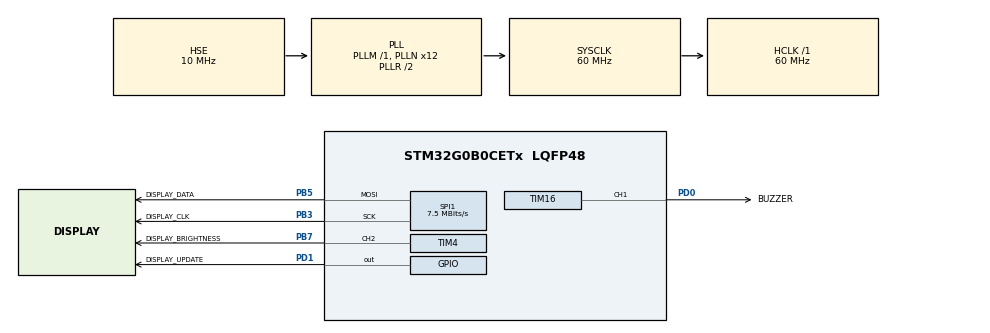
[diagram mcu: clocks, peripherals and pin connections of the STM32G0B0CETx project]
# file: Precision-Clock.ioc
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Dma.Request0=SPI1_TX
Dma.SPI1_TX.0.Direction=DMA_MEMORY_TO_PERIPH
Dma.SPI1_TX.0.EventEnable=DISABLE
Dma.SPI1_TX.0.Instance=DMA1_Channel1
Dma.SPI1_TX.0.MemDataAlignment=DMA_MDATAALIGN_BYTE
Dma.SPI1_TX.0.MemInc=DMA_MINC_ENABLE
Dma.SPI1_TX.0.Mode=DMA_NORMAL
Dma.SPI1_TX.0.PeriphDataAlignment=DMA_PDATAALIGN_BYTE
Dma.SPI1_TX.0.PeriphInc=DMA_PINC_DISABLE
Dma.SPI1_TX.0.Polarity=HAL_DMAMUX_REQ_GEN_RISING
Dma.SPI1_TX.0.Priority=DMA_PRIORITY_HIGH
Dma.SPI1_TX.0.RequestNumber=1
Dma.SPI1_TX.0.SignalID=NONE
Dma.SPI1_TX.0.SyncEnable=DISABLE
Dma.SPI1_TX.0.SyncPolarity=HAL_DMAMUX_SYNC_NO_EVENT
Dma.SPI1_TX.0.SyncRequestNumber=1
Dma.SPI1_TX.0.SyncSignalID=NONE
FREERTOS.Tasks01=defaultTask,24,512,StartDefaultTask,Default,NULL,Dynamic,NULL,NULL;brightnessTask,24,512,startBrightnessTask,As weak,NULL,Static,brightnessTaskBuffer,brightnessTaskControlBlock;displayRefreshTask,24,512,startDisplayRefreshTask,As weak,NULL,Static,displayRefreshTaskBuffer,displayRefreshTaskControlBlock
FREERTOS.configMAX_TASK_NAME_LEN=32
FREERTOS.configMINIMAL_STACK_SIZE=512
Mcu.Family=STM32G0
Mcu.Name=STM32G0B0CETx
Mcu.Package=LQFP48
NVIC.DMA1_Channel1_IRQn=true\:3\:0\:false\:false\:true\:true\:false\:true\:true
NVIC.TIM6_IRQn=true\:3\:0\:false\:false\:true\:false\:false\:true\:true
NVIC.TimeBase=TIM6_IRQn
NVIC.TimeBaseIP=TIM6
PA13.Mode=Serial_Wire
PA13.Signal=SYS_SWDIO
PA14-BOOT0.Mode=Serial_Wire
PA14-BOOT0.Signal=SYS_SWCLK
PB3.GPIO_Label=DISPLAY_CLK
PB3.GPIO_Speed=GPIO_SPEED_FREQ_VERY_HIGH
PB3.Mode=TX_Only_Simplex_Unidirect_Master
PB3.PinState=GPIO_PIN_RESET
PB3.Signal=SPI1_SCK
PB5.GPIO_Label=DISPLAY_DATA
PB5.GPIO_Speed=GPIO_SPEED_FREQ_VERY_HIGH
PB5.Mode=TX_Only_Simplex_Unidirect_Master
PB5.PinState=GPIO_PIN_RESET
PB5.Signal=SPI1_MOSI
PB7.GPIO_Label=DISPLAY_BRIGHTNESS
PB7.GPIO_Speed=GPIO_SPEED_FREQ_HIGH
PB7.Signal=S_TIM4_CH2
PC14-OSC32_IN\ (PC14).Mode=LSE-External-Oscillator
PC14-OSC32_IN\ (PC14).Signal=RCC_OSC32_IN
PC15-OSC32_OUT\ (PC15).Mode=LSE-External-Oscillator
PC15-OSC32_OUT\ (PC15).Signal=RCC_OSC32_OUT
PD0.GPIO_Label=BUZZER
PD0.Signal=S_TIM16_CH1
PD1.GPIO_Label=DISPLAY_UPDATE
PD1.GPIO_PuPd=GPIO_PULLDOWN
PD1.GPIO_Speed=GPIO_SPEED_FREQ_HIGH
PD1.Signal=GPIO_Output
PF0-OSC_IN\ (PF0).Mode=HSE-External-Clock-Source
PF0-OSC_IN\ (PF0).Signal=RCC_OSC_IN
ProjectManager.HeapSize=0x200
ProjectManager.StackSize=0x400
ProjectManager.TargetToolchain=CMake
RCC.ADCFreq_Value=60000000
RCC.AHBFreq_Value=60000000
RCC.CortexFreq_Value=60000000
RCC.EXTERNAL_CLOCK_VALUE=48000
RCC.HCLKFreq_Value=60000000
RCC.HSE_VALUE=10000000
RCC.HSI_VALUE=16000000
RCC.PLLN=12
RCC.PLLQ=RCC_PLLQ_DIV5
RCC.PLLSourceVirtual=RCC_PLLSOURCE_HSE
RCC.RTCClockSelection=RCC_RTCCLKSOURCE_LSE
RCC.SYSCLKFreq_VALUE=60000000
RCC.SYSCLKSource=RCC_SYSCLKSOURCE_PLLCLK
RCC.USBFreq_Value=24000000
RCC.VCOOutputFreq_Value=120000000
SH.S_TIM16_CH1.0=TIM16_CH1,PWM Generation1 CH1
SH.S_TIM4_CH2.0=TIM4_CH2,PWM Generation2 CH2
SPI1.BaudRatePrescaler=SPI_BAUDRATEPRESCALER_8
SPI1.CalculateBaudRate=7.5 MBits/s
SPI1.DataSize=SPI_DATASIZE_8BIT
SPI1.Direction=SPI_DIRECTION_2LINES
SPI1.Mode=SPI_MODE_MASTER
SPI1.NSSPMode=SPI_NSS_PULSE_DISABLE
SPI1.VirtualType=VM_MASTER
TIM16.AutoReloadPreload=TIM_AUTORELOAD_PRELOAD_ENABLE
TIM16.Channel=TIM_CHANNEL_1
TIM16.Period=999
TIM16.Prescaler=17143-1
TIM16.Pulse=999
TIM4.AutoReloadPreload=TIM_AUTORELOAD_PRELOAD_ENABLE
TIM4.Channel-PWM\ Generation2\ CH2=TIM_CHANNEL_2
TIM4.OCMode_PWM-PWM\ Generation2\ CH2=TIM_OCMODE_PWM1
TIM4.Period=999
TIM4.Prescaler=6-1
TIM4.Pulse-PWM\ Generation2\ CH2=999
VP_FREERTOS_VS_CMSIS_V2.Mode=CMSIS_V2
VP_RTC_VS_RTC_Activate.Mode=RTC_Enabled
VP_SYS_VS_DBSignals.Mode=DisableDeadBatterySignals
VP_SYS_VS_tim6.Mode=TIM6
VP_TIM16_VS_ClockSourceINT.Mode=Enable_Timer
VP_TIM4_VS_ClockSourceINT.Mode=Internal
board=custom

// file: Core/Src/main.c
/* USER CODE BEGIN Header */
/**
  ******************************************************************************
  * @file           : main.c
  * @brief          : Main program body
  ******************************************************************************
  * @attention
  *
  * Copyright (c) 2026 STMicroelectronics.
  * All rights reserved.
  *
  * This software is licensed under terms that can be found in the LICENSE file
  * in the root directory of this software component.
  * If no LICENSE file comes with this software, it is provided AS-IS.
  *
  ******************************************************************************
  */
/* USER CODE END Header */
#include "main.h"
#include "cmsis_os.h"

typedef StaticTask_t osStaticThreadDef_t;

RTC_HandleTypeDef hrtc;

SPI_HandleTypeDef hspi1;
DMA_HandleTypeDef hdma_spi1_tx;

TIM_HandleTypeDef htim4;
TIM_HandleTypeDef htim16;

/* Definitions for defaultTask */
osThreadId_t defaultTaskHandle;
const osThreadAttr_t defaultTask_attributes = {
  .name = "defaultTask",
  .priority = (osPriority_t) osPriorityNormal,
  .stack_size = 512 * 4
};
/* Definitions for brightnessTask */
osThreadId_t brightnessTaskHandle;
uint32_t brightnessTaskBuffer[ 512 ];
osStaticThreadDef_t brightnessTaskControlBlock;
const osThreadAttr_t brightnessTask_attributes = {
  .name = "brightnessTask",
  .stack_mem = &brightnessTaskBuffer[0],
  .stack_size = sizeof(brightnessTaskBuffer),
  .cb_mem = &brightnessTaskControlBlock,
  .cb_size = sizeof(brightnessTaskControlBlock),
  .priority = (osPriority_t) osPriorityNormal,
};
/* Definitions for displayRefreshTask */
osThreadId_t displayRefreshTaskHandle;
uint32_t displayRefreshTaskBuffer[ 512 ];
osStaticThreadDef_t displayRefreshTaskControlBlock;
const osThreadAttr_t displayRefreshTask_attributes = {
  .name = "displayRefreshTask",
  .stack_mem = &displayRefreshTaskBuffer[0],
  .stack_size = sizeof(displayRefreshTaskBuffer),
  .cb_mem = &displayRefreshTaskControlBlock,
  .cb_size = sizeof(displayRefreshTaskControlBlock),
  .priority = (osPriority_t) osPriorityNormal,
};

void SystemClock_Config(void);
static void MX_GPIO_Init(void);
static void MX_DMA_Init(void);
static void MX_SPI1_Init(void);
static void MX_TIM4_Init(void);
static void MX_RTC_Init(void);
static void MX_TIM16_Init(void);
void StartDefaultTask(void *argument);
void startBrightnessTask(void *argument);
void startDisplayRefreshTask(void *argument);

int main(void)
{

  /* MCU Configuration--------------------------------------------------------*/

  /* Reset of all peripherals, Initializes the Flash interface and the Systick. */
  HAL_Init();

  /* Configure the system clock */
  SystemClock_Config();

  /* Initialize all configured peripherals */
  MX_GPIO_Init();
  MX_DMA_Init();
  MX_SPI1_Init();
  MX_TIM4_Init();
  MX_RTC_Init();
  MX_TIM16_Init();

  /* Init scheduler */
  osKernelInitialize();

  /* Create the thread(s) */
  /* creation of defaultTask */
  defaultTaskHandle = osThreadNew(StartDefaultTask, NULL, &defaultTask_attributes);

  /* creation of brightnessTask */
  brightnessTaskHandle = osThreadNew(startBrightnessTask, NULL, &brightnessTask_attributes);

  /* creation of displayRefreshTask */
  displayRefreshTaskHandle = osThreadNew(startDisplayRefreshTask, NULL, &displayRefreshTask_attributes);

  /* Start scheduler */
  osKernelStart();

  /* We should never get here as control is now taken by the scheduler */

  /* Infinite loop */
  while (1)
  {

  }
}

void SystemClock_Config(void)
{
  RCC_OscInitTypeDef RCC_OscInitStruct = {0};
  RCC_ClkInitTypeDef RCC_ClkInitStruct = {0};

  /** Configure the main internal regulator output voltage
  */
  HAL_PWREx_ControlVoltageScaling(PWR_REGULATOR_VOLTAGE_SCALE1);

  /** Configure LSE Drive Capability
  */
  HAL_PWR_EnableBkUpAccess();
  __HAL_RCC_LSEDRIVE_CONFIG(RCC_LSEDRIVE_LOW);

  /** Initializes the RCC Oscillators according to the specified parameters
  * in the RCC_OscInitTypeDef structure.
  */
  RCC_OscInitStruct.OscillatorType = RCC_OSCILLATORTYPE_HSE|RCC_OSCILLATORTYPE_LSE;
  RCC_OscInitStruct.HSEState = RCC_HSE_BYPASS;
  RCC_OscInitStruct.LSEState = RCC_LSE_ON;
  RCC_OscInitStruct.PLL.PLLState = RCC_PLL_ON;
  RCC_OscInitStruct.PLL.PLLSource = RCC_PLLSOURCE_HSE;
  RCC_OscInitStruct.PLL.PLLM = RCC_PLLM_DIV1;
  RCC_OscInitStruct.PLL.PLLN = 12;
  RCC_OscInitStruct.PLL.PLLP = RCC_PLLP_DIV2;
  RCC_OscInitStruct.PLL.PLLQ = RCC_PLLQ_DIV5;
  RCC_OscInitStruct.PLL.PLLR = RCC_PLLR_DIV2;
  if (HAL_RCC_OscConfig(&RCC_OscInitStruct) != HAL_OK)
  {
    Error_Handler();
  }

  /** Initializes the CPU, AHB and APB buses clocks
  */
  RCC_ClkInitStruct.ClockType = RCC_CLOCKTYPE_HCLK|RCC_CLOCKTYPE_SYSCLK
                              |RCC_CLOCKTYPE_PCLK1;
  RCC_ClkInitStruct.SYSCLKSource = RCC_SYSCLKSOURCE_PLLCLK;
  RCC_ClkInitStruct.AHBCLKDivider = RCC_SYSCLK_DIV1;
  RCC_ClkInitStruct.APB1CLKDivider = RCC_HCLK_DIV1;

  if (HAL_RCC_ClockConfig(&RCC_ClkInitStruct, FLASH_LATENCY_2) != HAL_OK)
  {
    Error_Handler();
  }
}

static void MX_RTC_Init(void)
{

  /** Initialize RTC Only
  */
  hrtc.Instance = RTC;
  hrtc.Init.HourFormat = RTC_HOURFORMAT_24;
  hrtc.Init.AsynchPrediv = 127;
  hrtc.Init.SynchPrediv = 255;
  hrtc.Init.OutPut = RTC_OUTPUT_DISABLE;
  hrtc.Init.OutPutRemap = RTC_OUTPUT_REMAP_NONE;
  hrtc.Init.OutPutPolarity = RTC_OUTPUT_POLARITY_HIGH;
  hrtc.Init.OutPutType = RTC_OUTPUT_TYPE_OPENDRAIN;
  hrtc.Init.OutPutPullUp = RTC_OUTPUT_PULLUP_NONE;
  if (HAL_RTC_Init(&hrtc) != HAL_OK)
  {
    Error_Handler();
  }

}

static void MX_SPI1_Init(void)
{

  /* SPI1 parameter configuration*/
  hspi1.Instance = SPI1;
  hspi1.Init.Mode = SPI_MODE_MASTER;
  hspi1.Init.Direction = SPI_DIRECTION_2LINES;
  hspi1.Init.DataSize = SPI_DATASIZE_8BIT;
  hspi1.Init.CLKPolarity = SPI_POLARITY_LOW;
  hspi1.Init.CLKPhase = SPI_PHASE_1EDGE;
  hspi1.Init.NSS = SPI_NSS_SOFT;
  hspi1.Init.BaudRatePrescaler = SPI_BAUDRATEPRESCALER_8;
  hspi1.Init.FirstBit = SPI_FIRSTBIT_MSB;
  hspi1.Init.TIMode = SPI_TIMODE_DISABLE;
  hspi1.Init.CRCCalculation = SPI_CRCCALCULATION_DISABLE;
  hspi1.Init.CRCPolynomial = 7;
  hspi1.Init.CRCLength = SPI_CRC_LENGTH_DATASIZE;
  hspi1.Init.NSSPMode = SPI_NSS_PULSE_DISABLE;
  if (HAL_SPI_Init(&hspi1) != HAL_OK)
  {
    Error_Handler();
  }

}

static void MX_TIM4_Init(void)
{

  TIM_ClockConfigTypeDef sClockSourceConfig = {0};
  TIM_MasterConfigTypeDef sMasterConfig = {0};
  TIM_OC_InitTypeDef sConfigOC = {0};

  htim4.Instance = TIM4;
  htim4.Init.Prescaler = 6-1;
  htim4.Init.CounterMode = TIM_COUNTERMODE_UP;
  htim4.Init.Period = 999;
  htim4.Init.ClockDivision = TIM_CLOCKDIVISION_DIV1;
  htim4.Init.AutoReloadPreload = TIM_AUTORELOAD_PRELOAD_ENABLE;
  if (HAL_TIM_Base_Init(&htim4) != HAL_OK)
  {
    Error_Handler();
  }
  sClockSourceConfig.ClockSource = TIM_CLOCKSOURCE_INTERNAL;
  if (HAL_TIM_ConfigClockSource(&htim4, &sClockSourceConfig) != HAL_OK)
  {
    Error_Handler();
  }
  if (HAL_TIM_PWM_Init(&htim4) != HAL_OK)
  {
    Error_Handler();
  }
  sMasterConfig.MasterOutputTrigger = TIM_TRGO_RESET;
  sMasterConfig.MasterSlaveMode = TIM_MASTERSLAVEMODE_DISABLE;
  if (HAL_TIMEx_MasterConfigSynchronization(&htim4, &sMasterConfig) != HAL_OK)
  {
    Error_Handler();
  }
  sConfigOC.OCMode = TIM_OCMODE_PWM1;
  sConfigOC.Pulse = 999;
  sConfigOC.OCPolarity = TIM_OCPOLARITY_HIGH;
  sConfigOC.OCFastMode = TIM_OCFAST_DISABLE;
  if (HAL_TIM_PWM_ConfigChannel(&htim4, &sConfigOC, TIM_CHANNEL_2) != HAL_OK)
  {
    Error_Handler();
  }
  HAL_TIM_MspPostInit(&htim4);

}

static void MX_TIM16_Init(void)
{

  TIM_OC_InitTypeDef sConfigOC = {0};
  TIM_BreakDeadTimeConfigTypeDef sBreakDeadTimeConfig = {0};

  htim16.Instance = TIM16;
  htim16.Init.Prescaler = 17143-1;
  htim16.Init.CounterMode = TIM_COUNTERMODE_UP;
  htim16.Init.Period = 999;
  htim16.Init.ClockDivision = TIM_CLOCKDIVISION_DIV1;
  htim16.Init.RepetitionCounter = 0;
  htim16.Init.AutoReloadPreload = TIM_AUTORELOAD_PRELOAD_ENABLE;
  if (HAL_TIM_Base_Init(&htim16) != HAL_OK)
  {
    Error_Handler();
  }
  if (HAL_TIM_PWM_Init(&htim16) != HAL_OK)
  {
    Error_Handler();
  }
  sConfigOC.OCMode = TIM_OCMODE_PWM1;
  sConfigOC.Pulse = 999;
  sConfigOC.OCPolarity = TIM_OCPOLARITY_HIGH;
  sConfigOC.OCNPolarity = TIM_OCNPOLARITY_HIGH;
  sConfigOC.OCFastMode = TIM_OCFAST_DISABLE;
  sConfigOC.OCIdleState = TIM_OCIDLESTATE_RESET;
  sConfigOC.OCNIdleState = TIM_OCNIDLESTATE_RESET;
  if (HAL_TIM_PWM_ConfigChannel(&htim16, &sConfigOC, TIM_CHANNEL_1) != HAL_OK)
  {
    Error_Handler();
  }
  sBreakDeadTimeConfig.OffStateRunMode = TIM_OSSR_DISABLE;
  sBreakDeadTimeConfig.OffStateIDLEMode = TIM_OSSI_DISABLE;
  sBreakDeadTimeConfig.LockLevel = TIM_LOCKLEVEL_OFF;
  sBreakDeadTimeConfig.DeadTime = 0;
  sBreakDeadTimeConfig.BreakState = TIM_BREAK_DISABLE;
  sBreakDeadTimeConfig.BreakPolarity = TIM_BREAKPOLARITY_HIGH;
  sBreakDeadTimeConfig.BreakFilter = 0;
  sBreakDeadTimeConfig.AutomaticOutput = TIM_AUTOMATICOUTPUT_DISABLE;
  if (HAL_TIMEx_ConfigBreakDeadTime(&htim16, &sBreakDeadTimeConfig) != HAL_OK)
  {
    Error_Handler();
  }
  HAL_TIM_MspPostInit(&htim16);

}

static void MX_DMA_Init(void)
{

  /* DMA controller clock enable */
  __HAL_RCC_DMA1_CLK_ENABLE();

  /* DMA interrupt init */
  /* DMA1_Channel1_IRQn interrupt configuration */
  HAL_NVIC_SetPriority(DMA1_Channel1_IRQn, 3, 0);
  HAL_NVIC_EnableIRQ(DMA1_Channel1_IRQn);

}

static void MX_GPIO_Init(void)
{
  GPIO_InitTypeDef GPIO_InitStruct = {0};

  /* GPIO Ports Clock Enable */
  __HAL_RCC_GPIOC_CLK_ENABLE();
  __HAL_RCC_GPIOF_CLK_ENABLE();
  __HAL_RCC_GPIOA_CLK_ENABLE();
  __HAL_RCC_GPIOD_CLK_ENABLE();
  __HAL_RCC_GPIOB_CLK_ENABLE();

  /*Configure GPIO pin Output Level */
  HAL_GPIO_WritePin(DISPLAY_UPDATE_GPIO_Port, DISPLAY_UPDATE_Pin, GPIO_PIN_RESET);

  /*Configure GPIO pin : DISPLAY_UPDATE_Pin */
  GPIO_InitStruct.Pin = DISPLAY_UPDATE_Pin;
  GPIO_InitStruct.Mode = GPIO_MODE_OUTPUT_PP;
  GPIO_InitStruct.Pull = GPIO_PULLDOWN;
  GPIO_InitStruct.Speed = GPIO_SPEED_FREQ_HIGH;
  HAL_GPIO_Init(DISPLAY_UPDATE_GPIO_Port, &GPIO_InitStruct);

}

void StartDefaultTask(void *argument)
{
  /* USER CODE BEGIN 5 */
  /* Infinite loop */
  for(;;)
  {
    osDelay(1U);
  }
  /* USER CODE END 5 */
}

__weak void startBrightnessTask(void *argument)
{
  for(;;)
  {
    osDelay(1);
  }
}

__weak void startDisplayRefreshTask(void *argument)
{
  for(;;)
  {
    osDelay(1);
  }
}

void HAL_TIM_PeriodElapsedCallback(TIM_HandleTypeDef *htim)
{
  if (htim->Instance == TIM6)
  {
    HAL_IncTick();
  }
}

void Error_Handler(void)
{
  __disable_irq();
  while (1)
  {
  }
}
